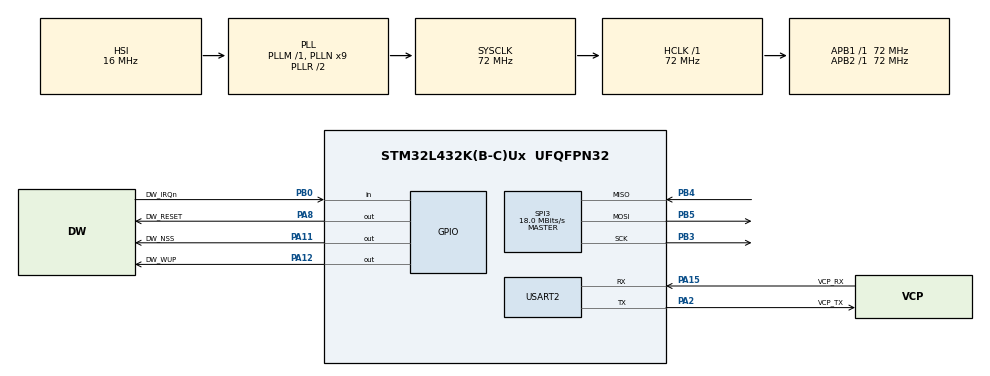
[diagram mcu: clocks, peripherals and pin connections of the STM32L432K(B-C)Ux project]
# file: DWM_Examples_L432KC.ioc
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Mcu.Family=STM32L4
Mcu.Name=STM32L432K(B-C)Ux
Mcu.Package=UFQFPN32
NVIC.PriorityGroup=NVIC_PRIORITYGROUP_4
PA0.GPIO_Label=MCO [High speed clock in]
PA0.Mode=HSE-External-Clock-Source-for-LittleOrca
PA0.Signal=RCC_CK_IN
PA11.GPIO_Label=DW_NSS
PA11.Signal=GPIO_Output
PA12.GPIO_Label=DW_WUP
PA12.Signal=GPIO_Output
PA13\ (JTMS-SWDIO).GPIO_Label=SWDIO
PA13\ (JTMS-SWDIO).Mode=Serial_Wire
PA13\ (JTMS-SWDIO).Signal=SYS_JTMS-SWDIO
PA14\ (JTCK-SWCLK).GPIO_Label=SWCLK
PA14\ (JTCK-SWCLK).Mode=Serial_Wire
PA14\ (JTCK-SWCLK).Signal=SYS_JTCK-SWCLK
PA15\ (JTDI).GPIO_Label=VCP_RX
PA15\ (JTDI).Mode=Asynchronous
PA15\ (JTDI).Signal=USART2_RX
PA2.GPIO_Label=VCP_TX
PA2.Mode=Asynchronous
PA2.Signal=USART2_TX
PA8.GPIO_Label=DW_RESET
PA8.GPIO_PuPd=GPIO_PULLUP
PA8.GPIO_Speed=GPIO_SPEED_FREQ_HIGH
PA8.PinState=GPIO_PIN_SET
PA8.Signal=GPIO_Output
PB0.GPIO_Label=DW_IRQn
PB0.GPIO_PuPd=GPIO_PULLUP
PB0.Signal=GPIO_Input
PB3\ (JTDO-TRACESWO).GPIO_Speed=GPIO_SPEED_FREQ_LOW
PB3\ (JTDO-TRACESWO).Mode=Full_Duplex_Master
PB3\ (JTDO-TRACESWO).Signal=SPI3_SCK
PB4\ (NJTRST).GPIO_Speed=GPIO_SPEED_FREQ_LOW
PB4\ (NJTRST).Mode=Full_Duplex_Master
PB4\ (NJTRST).Signal=SPI3_MISO
PB5.GPIO_Speed=GPIO_SPEED_FREQ_LOW
PB5.Mode=Full_Duplex_Master
PB5.Signal=SPI3_MOSI
PC14-OSC32_IN\ (PC14).Mode=LSE-External-Oscillator
PC14-OSC32_IN\ (PC14).Signal=RCC_OSC32_IN
PC15-OSC32_OUT\ (PC15).Mode=LSE-External-Oscillator
PC15-OSC32_OUT\ (PC15).Signal=RCC_OSC32_OUT
ProjectManager.HeapSize=0x200
ProjectManager.StackSize=0x400
ProjectManager.TargetToolchain=STM32CubeIDE
RCC.ADCFreq_Value=64000000
RCC.AHBFreq_Value=72000000
RCC.APB1Freq_Value=72000000
RCC.APB1TimFreq_Value=72000000
RCC.APB2Freq_Value=72000000
RCC.APB2TimFreq_Value=72000000
RCC.CortexFreq_Value=72000000
RCC.HCLKFreq_Value=72000000
RCC.HSE_VALUE=8000000
RCC.HSI16_VALUE=16000000
RCC.HSI48_VALUE=48000000
RCC.HSI_VALUE=16000000
RCC.MSI_VALUE=4000000
RCC.PLLMUL=RCC_PLLMUL_4
RCC.PLLN=9
RCC.PLLSourceVirtual=RCC_PLLSOURCE_HSI
RCC.SYSCLKFreq_VALUE=72000000
RCC.SYSCLKSource=RCC_SYSCLKSOURCE_PLLCLK
RCC.USBFreq_Value=64000000
RCC.VCOOutputFreq_Value=144000000
SPI3.BaudRatePrescaler=SPI_BAUDRATEPRESCALER_4
SPI3.CalculateBaudRate=18.0 MBits/s
SPI3.DataSize=SPI_DATASIZE_8BIT
SPI3.Direction=SPI_DIRECTION_2LINES
SPI3.Mode=SPI_MODE_MASTER
SPI3.VirtualType=VM_MASTER
TIM2.Prescaler=71
USART2.VirtualMode-Asynchronous=VM_ASYNC
VP_TIM2_VS_ClockSourceINT.Mode=Internal
board=NUCLEO-L432KC

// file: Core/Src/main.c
/* USER CODE BEGIN Header */
/**
  ******************************************************************************
  * @file           : main.c
  * @brief          : Main program body
  ******************************************************************************
  * @attention
  *
  * Copyright (c) 2022 STMicroelectronics.
  * All rights reserved.
  *
  * This software is licensed under terms that can be found in the LICENSE file
  * in the root directory of this software component.
  * If no LICENSE file comes with this software, it is provided AS-IS.
  *
  ******************************************************************************
  */
/* USER CODE END Header */
#include "main.h"
#include "spi.h"
#include "tim.h"
#include "usart.h"
#include "gpio.h"

/* USER CODE BEGIN Includes */
#include "examples_defines.h"
#include "port.h"
#include "string.h"
/* USER CODE END Includes */

/* USER CODE BEGIN PD */
void test_run_info(unsigned char *data);
/* USER CODE END PD */

/* USER CODE BEGIN PV */
extern example_ptr example_pointer;
/* USER CODE END PV */

void SystemClock_Config(void);

int main(void)
{
  /* USER CODE BEGIN 1 */
  build_examples();
  /* USER CODE END 1 */

  /* MCU Configuration--------------------------------------------------------*/

  /* Reset of all peripherals, Initializes the Flash interface and the Systick. */
  HAL_Init();

  /* Configure the system clock */
  SystemClock_Config();

  /* Initialize all configured peripherals */
  MX_GPIO_Init();
  MX_USART2_UART_Init();
  MX_SPI3_Init();
  MX_TIM2_Init();
  /* USER CODE BEGIN 2 */
  port_DisableEXT_IRQ();
  example_pointer();
  /* USER CODE END 2 */

  /* Infinite loop */
  while (1)
  {

  }
}

void SystemClock_Config(void)
{
  RCC_OscInitTypeDef RCC_OscInitStruct = {0};
  RCC_ClkInitTypeDef RCC_ClkInitStruct = {0};

  /** Configure the main internal regulator output voltage
  */
  if (HAL_PWREx_ControlVoltageScaling(PWR_REGULATOR_VOLTAGE_SCALE1) != HAL_OK)
  {
    Error_Handler();
  }

  /** Initializes the RCC Oscillators according to the specified parameters
  * in the RCC_OscInitTypeDef structure.
  */
  RCC_OscInitStruct.OscillatorType = RCC_OSCILLATORTYPE_HSI;
  RCC_OscInitStruct.HSIState = RCC_HSI_ON;
  RCC_OscInitStruct.HSICalibrationValue = RCC_HSICALIBRATION_DEFAULT;
  RCC_OscInitStruct.PLL.PLLState = RCC_PLL_ON;
  RCC_OscInitStruct.PLL.PLLSource = RCC_PLLSOURCE_HSI;
  RCC_OscInitStruct.PLL.PLLM = 1;
  RCC_OscInitStruct.PLL.PLLN = 9;
  RCC_OscInitStruct.PLL.PLLP = RCC_PLLP_DIV7;
  RCC_OscInitStruct.PLL.PLLQ = RCC_PLLQ_DIV2;
  RCC_OscInitStruct.PLL.PLLR = RCC_PLLR_DIV2;
  if (HAL_RCC_OscConfig(&RCC_OscInitStruct) != HAL_OK)
  {
    Error_Handler();
  }

  /** Initializes the CPU, AHB and APB buses clocks
  */
  RCC_ClkInitStruct.ClockType = RCC_CLOCKTYPE_HCLK|RCC_CLOCKTYPE_SYSCLK
                              |RCC_CLOCKTYPE_PCLK1|RCC_CLOCKTYPE_PCLK2;
  RCC_ClkInitStruct.SYSCLKSource = RCC_SYSCLKSOURCE_PLLCLK;
  RCC_ClkInitStruct.AHBCLKDivider = RCC_SYSCLK_DIV1;
  RCC_ClkInitStruct.APB1CLKDivider = RCC_HCLK_DIV1;
  RCC_ClkInitStruct.APB2CLKDivider = RCC_HCLK_DIV1;

  if (HAL_RCC_ClockConfig(&RCC_ClkInitStruct, FLASH_LATENCY_4) != HAL_OK)
  {
    Error_Handler();
  }
}

/* USER CODE BEGIN 4 */
void test_run_info(unsigned char *data)
{
    uint16_t    data_length;

    data_length=strlen((const char *)data);
    HAL_UART_Transmit(&huart2, data, data_length, 10);/*Transmit the data through USB - Virtual port*/
    HAL_UART_Transmit(&huart2, (uint8_t*)"\n\r", 2, 10);/*Transmit end of line through USB - Virtual port*/

}
/* USER CODE END 4 */

void Error_Handler(void)
{
  __disable_irq();
  while (1)
  {
  }
}
